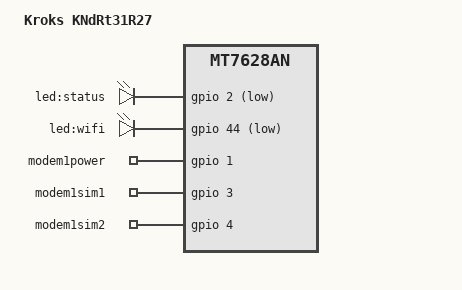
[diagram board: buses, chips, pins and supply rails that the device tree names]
#include "mt7628an_kroks_4reth.dtsi"

/ {
	compatible = "kroks,kndrt31r27", "mediatek,mt7628an-soc";
	model = "Kroks KNdRt31R27";

	aliases {
		led-boot = &led_status;
		led-failsafe = &led_status;
		led-running = &led_status;
		led-upgrade = &led_status;
	};

	leds {
		compatible = "gpio-leds";

		led_status: status {
			label = "led:status";
			gpios = <&gpio 2 GPIO_ACTIVE_LOW>;
		};

		wifi {
			label = "led:wifi";
			gpios = <&gpio 44 GPIO_ACTIVE_LOW>;
			linux,default-trigger = "phy0tpt";
		};
	};

	gpio_export {
		compatible = "gpio-export";
		#size-cells = <0>;

		modem1power {
			gpio-export,name = "modem1power";
			gpio-export,output = <1>;
			gpios = <&gpio 1 GPIO_ACTIVE_HIGH>;
		};

		modem1sim1 {
			gpio-export,name = "modem1sim1";
			gpio-export,output = <1>;
			gpios = <&gpio 3 GPIO_ACTIVE_HIGH>;
		};

		modem1sim2 {
			gpio-export,name = "modem1sim2";
			gpio-export,output = <0>;
			gpios = <&gpio 4 GPIO_ACTIVE_HIGH>;
		};
	};
};

&state_default {
	gpio {
		groups = "i2s", "i2c", "wled_an";
		function = "gpio";
	};
};
